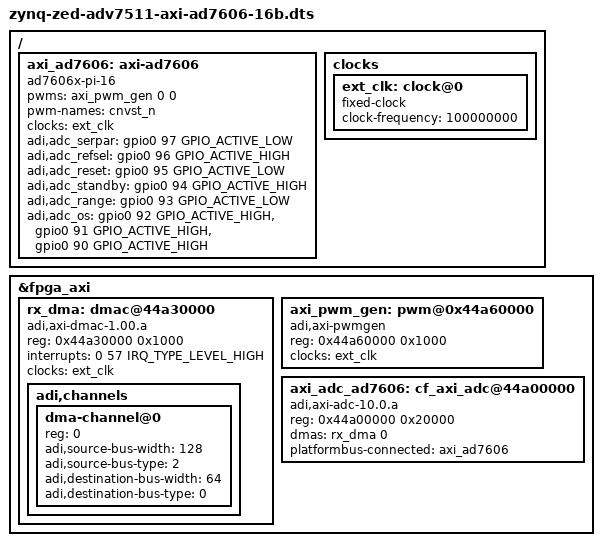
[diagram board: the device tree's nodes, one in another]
// SPDX-License-Identifier: GPL-2.0
/*
 * Analog Devices AD7606X
 *
 * hdl_project: <ad7606x_fmc/zed>
 * board_revision: <A>
 *
 * Copyright (C) 2023 Analog Devices Inc.
 */
/dts-v1/;

#include "zynq-zed.dtsi"
#include "zynq-zed-adv7511.dtsi"
#include <dt-bindings/gpio/gpio.h>
#include <dt-bindings/pwm/pwm.h>

/ {
	axi_ad7606: axi-ad7606 {
		compatible = "ad7606x-pi-16";

		pwms = <&axi_pwm_gen 0 0>;
		pwm-names = "cnvst_n";

		clocks = <&ext_clk>;
		clock-names = "ad7606x_pi_clk";

		adi,adc_serpar = <&gpio0 97 GPIO_ACTIVE_LOW>;
		adi,adc_refsel = <&gpio0 96 GPIO_ACTIVE_HIGH>;
		adi,adc_reset = <&gpio0 95 GPIO_ACTIVE_LOW>;
		adi,adc_standby = <&gpio0 94 GPIO_ACTIVE_HIGH>;
		adi,adc_range = <&gpio0 93 GPIO_ACTIVE_LOW>;
		adi,adc_os = <&gpio0 92 GPIO_ACTIVE_HIGH>,
			     <&gpio0 91 GPIO_ACTIVE_HIGH>,
			     <&gpio0 90 GPIO_ACTIVE_HIGH>;

	};
};

/ {
	clocks {
		ext_clk: clock@0 {
			#clock-cells = <0>;
			compatible = "fixed-clock";
			clock-frequency = <100000000>;
		};
	};
};

&fpga_axi {
	rx_dma: dmac@44a30000 {
		compatible = "adi,axi-dmac-1.00.a";
		reg = <0x44a30000 0x1000>;
		#dma-cells = <1>;
		interrupts = <0 57 IRQ_TYPE_LEVEL_HIGH>;
		clocks = <&ext_clk>;

		adi,channels {
			#size-cells = <0>;
			#address-cells = <1>;

			dma-channel@0 {
				reg = <0>;
				adi,source-bus-width = <128>;
				adi,source-bus-type = <2>;
				adi,destination-bus-width = <64>;
				adi,destination-bus-type = <0>;
			};
		};
	};

	axi_pwm_gen: pwm@0x44a60000 {
		compatible = "adi,axi-pwmgen";
		reg = <0x44a60000 0x1000>;
		#pwm-cells = <2>;
		clocks = <&ext_clk>;
	};

	axi_adc_ad7606: cf_axi_adc@44a00000 {
		compatible = "adi,axi-adc-10.0.a";
		reg = <0x44a00000 0x20000>;
		dmas = <&rx_dma 0>;
		dma-names = "rx";
		platformbus-connected = <&axi_ad7606>;
	};

};
